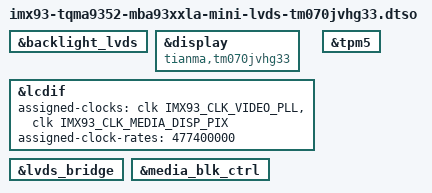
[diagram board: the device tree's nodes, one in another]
// SPDX-License-Identifier: (GPL-2.0-or-later OR MIT)
/*
 * Copyright (c) 2025 TQ-Systems GmbH <linux@ew.tq-group.com>,
 * D-82229 Seefeld, Germany.
 * Author: Martin Schmiedel
 */

#include <dt-bindings/clock/imx93-clock.h>

/dts-v1/;
/plugin/;

&backlight_lvds {
	status = "okay";
};

&display {
	compatible = "tianma,tm070jvhg33";
	status = "okay";
};

&lcdif {
	assigned-clocks = <&clk IMX93_CLK_VIDEO_PLL>,
			  <&clk IMX93_CLK_MEDIA_DISP_PIX>;
	assigned-clock-rates = <477400000>;
	status = "okay";
};

&lvds_bridge {
	status = "okay";
};

&media_blk_ctrl {
	status = "okay";
};

&tpm5 {
	status = "okay";
};
